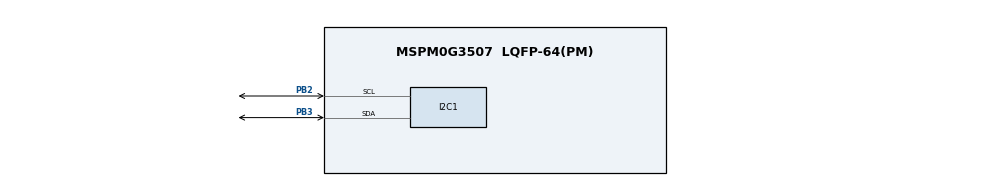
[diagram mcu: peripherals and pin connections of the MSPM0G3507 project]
/**
 * LP-MSPM0G3507 SSD1306 I2C baseline: PB2=SCL, PB3=SDA.
 */
//@cliArgs --device "MSPM0G350X" --package "LQFP-64(PM)" --part "Default"
//@v2CliArgs --device "MSPM0G3507" --package "LQFP-64(PM)"
// @cliArgs --board /ti/boards/LP_MSPM0G3507 --rtos nortos

const I2C  = scripting.addModule("/ti/driverlib/I2C", {}, false);
const I2C1 = I2C.addInstance();

I2C1.basicEnableController     = true;
I2C1.basicControllerBusSpeed   = 100000;
I2C1.$name                     = "I2C";
I2C1.advAnalogGlitchFilter     = "DISABLED";
I2C1.peripheral.sdaPin.$assign = "PB3";
I2C1.peripheral.sclPin.$assign = "PB2";

const Board = scripting.addModule("/ti/driverlib/Board", {}, false);

const SYSCTL                 = scripting.addModule("/ti/driverlib/SYSCTL", {}, false);
SYSCTL.forceDefaultClkConfig = true;
SYSCTL.clockTreeEn           = true;
